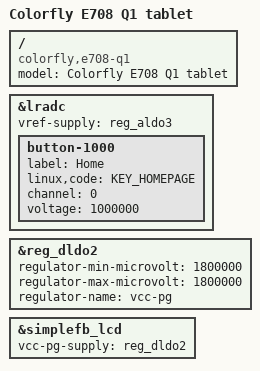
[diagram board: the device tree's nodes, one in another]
/dts-v1/;
#include "sun6i-a31s.dtsi"
#include "sun6i-reference-design-tablet.dtsi"
/ {
	model = "Colorfly E708 Q1 tablet";
	compatible = "colorfly,e708-q1", "allwinner,sun6i-a31s";
};
&lradc {
	vref-supply = <&reg_aldo3>;
	status = "okay";
	button-1000 {
		label = "Home";
		linux,code = <KEY_HOMEPAGE>;
		channel = <0>;
		voltage = <1000000>;
	};
};
&reg_dldo2 {
	regulator-min-microvolt = <1800000>;
	regulator-max-microvolt = <1800000>;
	regulator-name = "vcc-pg";
};
&simplefb_lcd {
	vcc-pg-supply = <&reg_dldo2>;
};
